# STM32WB35CCU6A register map
File version: 1.0
Registers are 32-bit, access not given, reset 0x0 unless marked. A register's access mark holds for its fields unless they carry their own. Offsets are from the block's base; [hi:lo] are bit positions; {n}, {i} and the like mark numbered series; 'fields as' and 'values as' point back to an identical list.

## LCD
Base 0x40002400
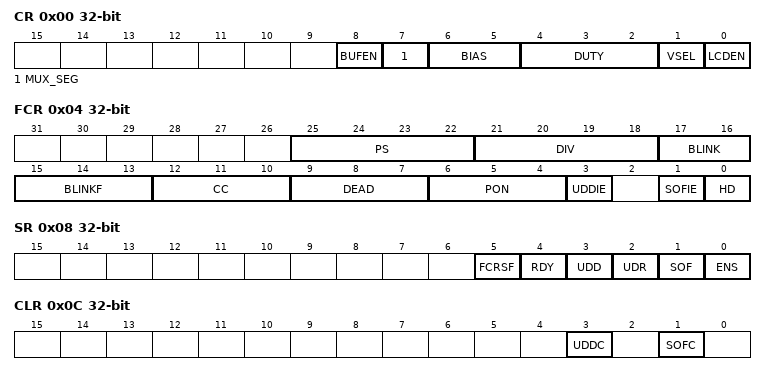
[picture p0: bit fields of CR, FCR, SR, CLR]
0x00 CR
  [8] BUFEN, [7] MUX_SEG, [6:5] BIAS, [4:2] DUTY, [1] VSEL, [0] LCDEN
0x04 FCR
  [25:22] PS, [21:18] DIV, [17:16] BLINK, [15:13] BLINKF, [12:10] CC, [9:7] DEAD, [6:4] PON, [3] UDDIE, [1] SOFIE, [0] HD
0x08 SR
  [5] FCRSF, [4] RDY, [3] UDD, [2] UDR, [1] SOF, [0] ENS
0x0C CLR
  [3] UDDC, [1] SOFC
{0x18+8i} RAM_COM{i} (i=0..7)

## TAMP
Base 0x40002800
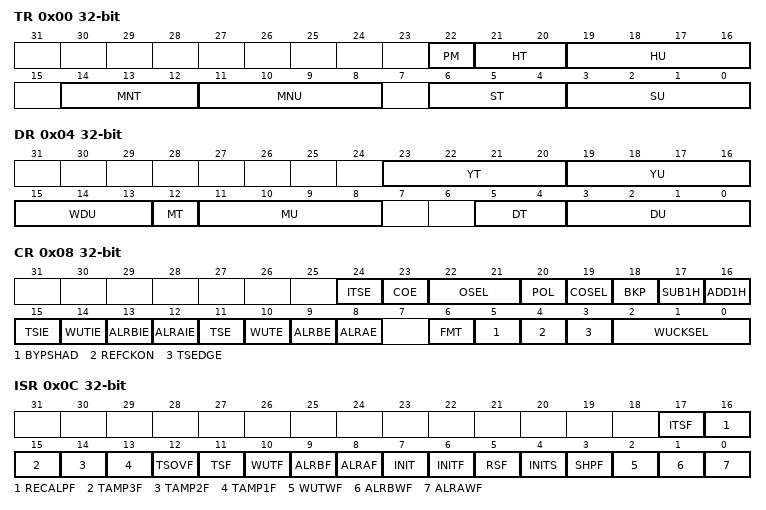
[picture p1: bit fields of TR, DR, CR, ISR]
0x00 TR
  [22] PM, [21:20] HT, [19:16] HU, [14:12] MNT, [11:8] MNU, [6:4] ST, [3:0] SU
0x04 DR
  [23:20] YT, [19:16] YU, [15:13] WDU, [12] MT, [11:8] MU, [5:4] DT, [3:0] DU
0x08 CR
  [24] ITSE, [23] COE, [22:21] OSEL, [20] POL, [19] COSEL, [18] BKP, [17] SUB1H, [16] ADD1H, [15] TSIE, [14] WUTIE, [13] ALRBIE, [12] ALRAIE, [11] TSE, [10] WUTE, [9] ALRBE, [8] ALRAE, [6] FMT, [5] BYPSHAD, [4] REFCKON, [3] TSEDGE, [2:0] WUCKSEL
0x0C ISR
  [17] ITSF, [16] RECALPF, [15] TAMP3F, [14] TAMP2F, [13] TAMP1F, [12] TSOVF, [11] TSF, [10] WUTF, [9] ALRBF, [8] ALRAF, [7] INIT, [6] INITF, [5] RSF, [4] INITS, [3] SHPF, [2] WUTWF, [1] ALRBWF, [0] ALRAWF
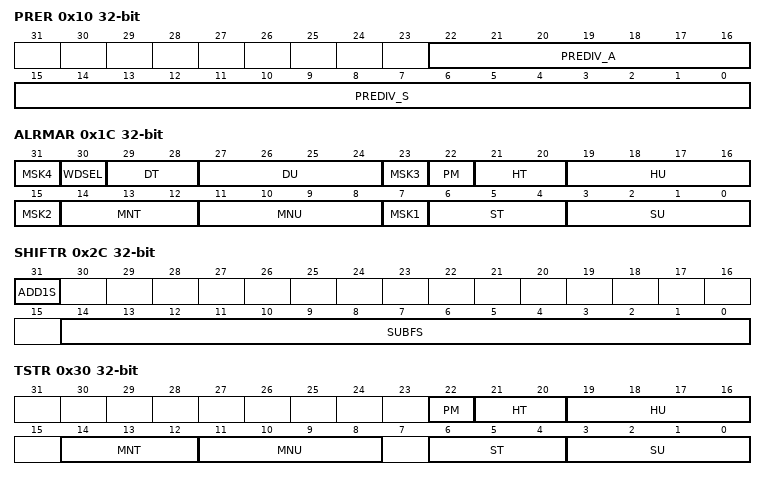
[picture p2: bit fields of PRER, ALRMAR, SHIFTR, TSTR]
0x10 PRER
  [22:16] PREDIV_A, [15:0] PREDIV_S
0x14 WUTR
  [15:0] WUT
0x1C ALRMAR
  [8n-1] MSK{n} (n=1..4), [30] WDSEL, [29:28] DT, [27:24] DU, [22] PM, [21:20] HT, [19:16] HU, [14:12] MNT, [11:8] MNU, [6:4] ST, [3:0] SU
0x20 ALRMBR
  [31] MSK4, [30] WDSEL, [29:28] DT, [27:24] DU, [23] MSK3, [22] PM, [21:20] HT, [19:16] HU, [14:12] MNT, [11:8] MNU, [15:7] MSK2, [6:4] ST, [3:0] SU
0x24 WPR
  [7:0] KEY
0x28 SSR
  [15:0] SS
0x2C SHIFTR
  [31] ADD1S, [14:0] SUBFS
0x30 TSTR
  fields as TR
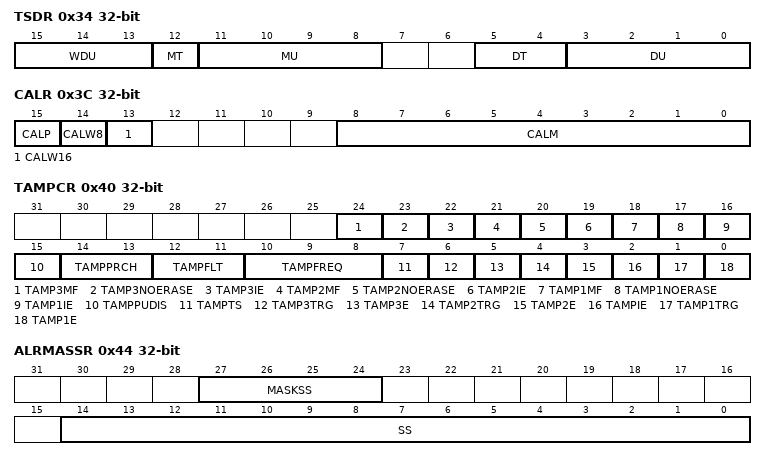
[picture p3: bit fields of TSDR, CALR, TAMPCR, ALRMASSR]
0x34 TSDR
  [15:13] WDU, [12] MT, [11:8] MU, [5:4] DT, [3:0] DU
0x38 TSSSR
  [15:0] SS
0x3C CALR
  [15] CALP, [14] CALW8, [13] CALW16, [8:0] CALM
0x40 TAMPCR
  [24] TAMP3MF, [23] TAMP3NOERASE, [22] TAMP3IE, [21] TAMP2MF, [20] TAMP2NOERASE, [19] TAMP2IE, [18] TAMP1MF, [17] TAMP1NOERASE, [16] TAMP1IE, [15] TAMPPUDIS, [14:13] TAMPPRCH, [12:11] TAMPFLT, [10:8] TAMPFREQ, [7] TAMPTS, [6] TAMP3TRG, [5] TAMP3E, [4] TAMP2TRG, [3] TAMP2E, [2] TAMPIE, [1] TAMP1TRG, [0] TAMP1E
0x44 ALRMASSR
  [27:24] MASKSS, [14:0] SS
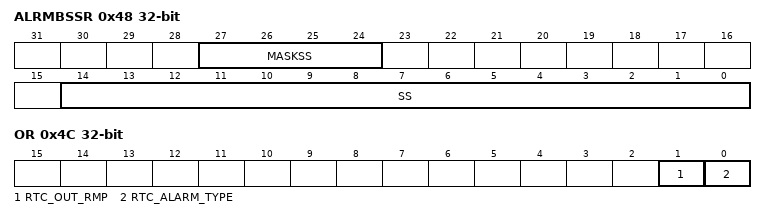
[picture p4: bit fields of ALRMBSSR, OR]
0x48 ALRMBSSR
  [27:24] MASKSS, [14:0] SS
0x4C OR
  [1] RTC_OUT_RMP, [0] RTC_ALARM_TYPE
{0x50+4i} BKP{i}R (i=0..19)
  [31:0] BKP

## RTC
Base 0x40002800
Registers as TAMP, without TAMPCR; these are added or differ:
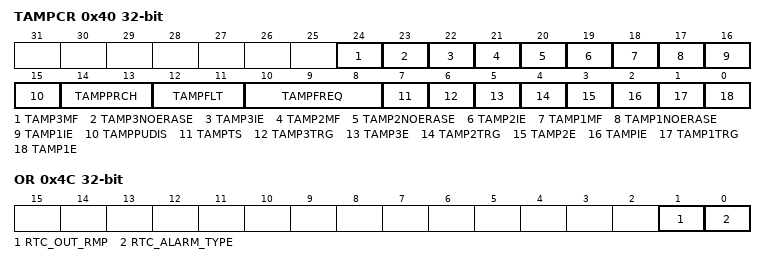
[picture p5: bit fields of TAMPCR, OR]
0x40 TAMPCR
  fields as TAMP.TAMPCR
0x4C OR
  [1] RTC_OUT_RMP, [0] RTC_ALARM_TYPE

## WWDG
Base 0x40002C00
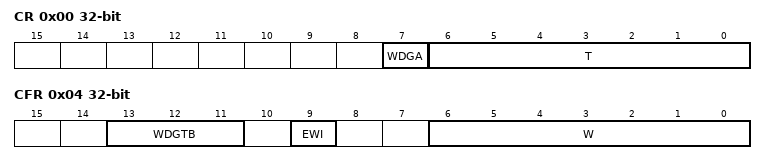
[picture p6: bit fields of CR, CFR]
0x00 CR
  [7] WDGA, [6:0] T
0x04 CFR
  [13:11] WDGTB, [9] EWI, [6:0] W
0x08 SR
  [0] EWIF

## IWDG
Base 0x40003000
0x00 KR
  [15:0] KEY
0x04 PR
  [2:0] PR
0x08 RLR
  [11:0] RL
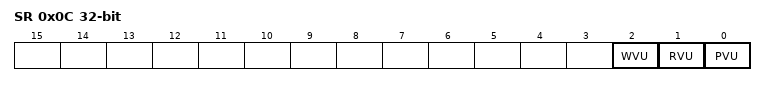
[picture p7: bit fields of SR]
0x0C SR
  [2] WVU, [1] RVU, [0] PVU
0x10 WINR
  [11:0] WIN

## SPI2
Base 0x40003800
Same registers: SPI1 0x40013000
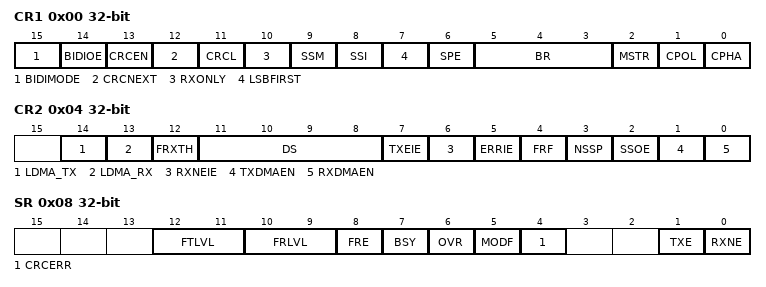
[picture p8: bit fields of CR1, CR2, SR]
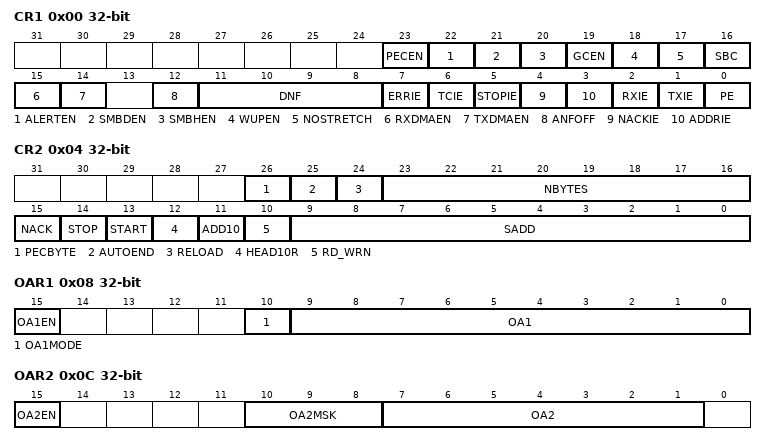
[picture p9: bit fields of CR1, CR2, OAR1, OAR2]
0x00 CR1
  [15] BIDIMODE, [14] BIDIOE, [13] CRCEN, [12] CRCNEXT, [11] CRCL, [10] RXONLY, [9] SSM, [8] SSI, [7] LSBFIRST, [6] SPE, [5:3] BR, [2] MSTR, [1] CPOL, [0] CPHA
0x04 CR2
  [14] LDMA_TX, [13] LDMA_RX, [12] FRXTH, [11:8] DS, [7] TXEIE, [6] RXNEIE, [5] ERRIE, [4] FRF, [3] NSSP, [2] SSOE, [1] TXDMAEN, [0] RXDMAEN
0x08 SR
  [12:11] FTLVL, [10:9] FRLVL, [8] FRE, [7] BSY, [6] OVR, [5] MODF, [4] CRCERR, [1] TXE, [0] RXNE
0x0C DR
  [15:0] DR
0x10 CRCPR
  [15:0] CRCPOLY
0x14 RXCRCR
  [15:0] RXCRC
0x18 TXCRCR
  [15:0] TXCRC

## I2C1
Base 0x40005400
Same registers: I2C3 0x40005C00
0x00 CR1
  [23] PECEN, [22] ALERTEN, [21] SMBDEN, [20] SMBHEN, [19] GCEN, [18] WUPEN, [17] NOSTRETCH, [16] SBC, [15] RXDMAEN, [14] TXDMAEN, [12] ANFOFF, [11:8] DNF, [7] ERRIE, [6] TCIE, [5] STOPIE, [4] NACKIE, [3] ADDRIE, [2] RXIE, [1] TXIE, [0] PE
0x04 CR2
  [26] PECBYTE, [25] AUTOEND, [24] RELOAD, [23:16] NBYTES, [15] NACK, [14] STOP, [13] START, [12] HEAD10R, [11] ADD10, [10] RD_WRN, [9:0] SADD
0x08 OAR1
  [15] OA1EN, [10] OA1MODE, [9:0] OA1
0x0C OAR2
  [15] OA2EN, [10:8] OA2MSK, [7:1] OA2
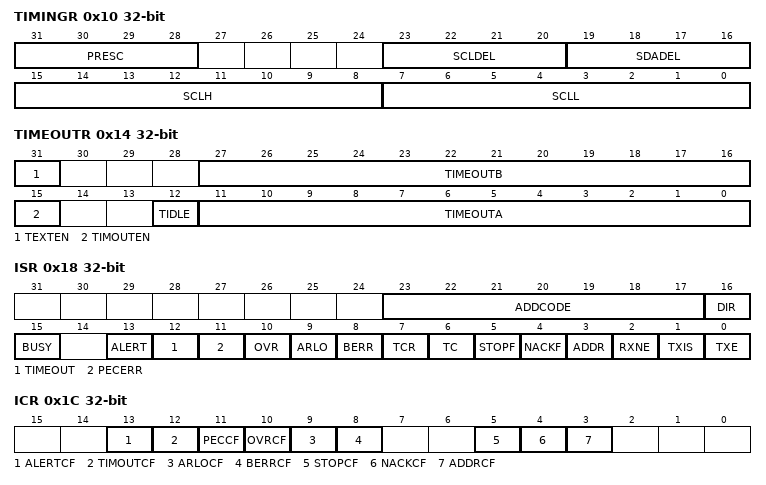
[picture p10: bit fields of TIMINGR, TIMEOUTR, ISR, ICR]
0x10 TIMINGR
  [31:28] PRESC, [23:20] SCLDEL, [19:16] SDADEL, [15:8] SCLH, [7:0] SCLL
0x14 TIMEOUTR
  [31] TEXTEN, [27:16] TIMEOUTB, [15] TIMOUTEN, [12] TIDLE, [11:0] TIMEOUTA
0x18 ISR
  [23:17] ADDCODE, [16] DIR, [15] BUSY, [13] ALERT, [12] TIMEOUT, [11] PECERR, [10] OVR, [9] ARLO, [8] BERR, [7] TCR, [6] TC, [5] STOPF, [4] NACKF, [3] ADDR, [2] RXNE, [1] TXIS, [0] TXE
0x1C ICR
  [13] ALERTCF, [12] TIMOUTCF, [11] PECCF, [10] OVRCF, [9] ARLOCF, [8] BERRCF, [5] STOPCF, [4] NACKCF, [3] ADDRCF
0x20 PECR
  [7:0] PEC
0x24 RXDR
  [7:0] RXDATA
0x28 TXDR
  [7:0] TXDATA
